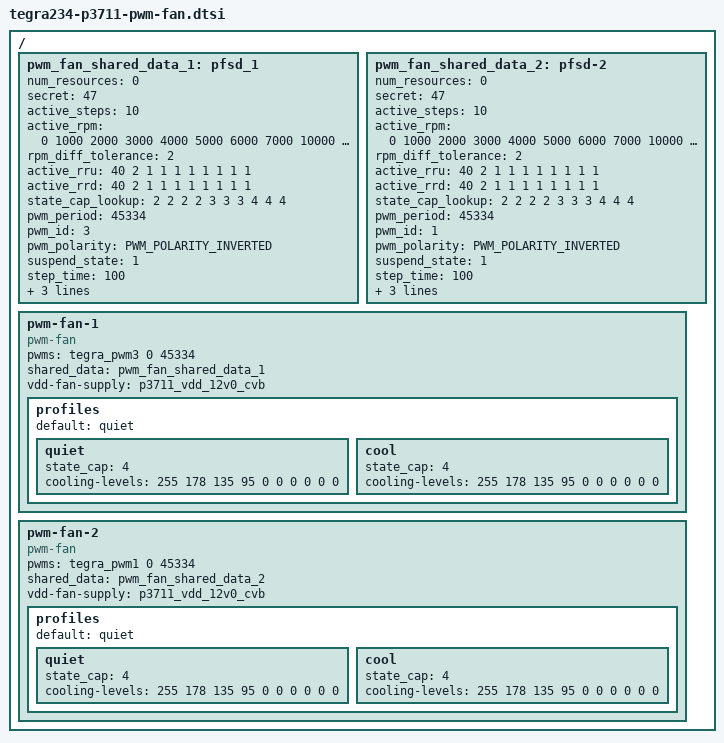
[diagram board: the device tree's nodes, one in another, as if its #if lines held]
/*
 * Copyright (c) 2021, NVIDIA CORPORATION.  All rights reserved.
 *
 * This program is free software; you can redistribute it and/or modify it
 * under the terms and conditions of the GNU General Public License,
 * version 2, as published by the Free Software Foundation.
 *
 * This program is distributed in the hope it will be useful, but WITHOUT
 * ANY WARRANTY; without even the implied warranty of MERCHANTABILITY or
 * FITNESS FOR A PARTICULAR PURPOSE.  See the GNU General Public License for
 * more details.
 *
 * You should have received a copy of the GNU General Public License
 * along with this program.  If not, see <http://www.gnu.org/licenses/>.
 */
#include <dt-bindings/gpio/tegra234-gpio.h>
#include <dt-bindings/pwm/pwm.h>

/ {
	pwm_fan_shared_data_1: pfsd_1 {
		num_resources = <0>;
		secret = <47>;
		active_steps = <10>;
		active_rpm = <0 1000 2000 3000 4000 5000 6000 7000 10000 11000>;
		rpm_diff_tolerance = <2>;
		active_rru = <40 2 1 1 1 1 1 1 1 1>;
		active_rrd = <40 2 1 1 1 1 1 1 1 1>;
		state_cap_lookup = <2 2 2 2 3 3 3 4 4 4>;
		pwm_period = <45334>;
		/* TODO: Check correctness of PWM controller ID when pinmux sheet is available */
		pwm_id = <3>;
		pwm_polarity = <PWM_POLARITY_INVERTED>;
		suspend_state = <1>;
		step_time = <100>; /* mesecs */
		state_cap = <7>;
		active_pwm_max = <256>;
		tach_period = <1000>;
		/* TODO: Fix when pinmux sheet is available */
		//pwm_gpio = <&tegra_aon_gpio TEGRA234_AON_GPIO(CC, 4) GPIO_ACTIVE_LOW>;
	};

	pwm_fan_shared_data_2: pfsd-2 {
		num_resources = <0>;
		secret = <47>;
		active_steps = <10>;
		active_rpm = <0 1000 2000 3000 4000 5000 6000 7000 10000 11000>;
		rpm_diff_tolerance = <2>;
		active_rru = <40 2 1 1 1 1 1 1 1 1>;
		active_rrd = <40 2 1 1 1 1 1 1 1 1>;
		state_cap_lookup = <2 2 2 2 3 3 3 4 4 4>;
		pwm_period = <45334>;
		/* TODO: Check correctness of PWM controller ID when pinmux sheet is available */
		pwm_id = <1>;
		pwm_polarity = <PWM_POLARITY_INVERTED>;
		suspend_state = <1>;
		step_time = <100>; /* mesecs */
		state_cap = <7>;
		active_pwm_max = <256>;
		tach_period = <1000>;
		/* TODO: Fix when pinmux sheet is available */
		//pwm_gpio = <&tegra_aon_gpio TEGRA234_AON_GPIO(CC, 4) GPIO_ACTIVE_LOW>;
	};

	/* PWM FAN on J16 */
	pwm-fan-1 {
		compatible = "pwm-fan";
		status = "okay";
		#pwm-cells = <1>;
		/* TODO: Check correctness of PWM controller ID when pinmux sheet is available */
		pwms = <&tegra_pwm3 0 45334>;
		shared_data = <&pwm_fan_shared_data_1>;
		vdd-fan-supply = <&p3711_vdd_12v0_cvb>;
		profiles {
			default = "quiet";
			quiet {
				state_cap = <4>;
#if TEGRA_PWM_FAN_DT_VERSION == DT_VERSION_2
				cooling-levels = <255 178 135 95 0 0 0 0 0 0>;
#else
				active_pwm = <0 77 120 160 255 255 255 255 255 255>;
#endif
			};
			cool {
				state_cap = <4>;
#if TEGRA_PWM_FAN_DT_VERSION == DT_VERSION_2
				cooling-levels = <255 178 135 95 0 0 0 0 0 0>;
#else
				active_pwm = <0 77 120 160 255 255 255 255 255 255>;
#endif
			};
		};
	};

	/* PWM FAN on J17 */
	pwm-fan-2 {
		compatible = "pwm-fan";
		status = "okay";
		#pwm-cells = <1>;
		/* TODO: Check correctness of PWM controller ID when pinmux sheet is available */
		pwms = <&tegra_pwm1 0 45334>;
		shared_data = <&pwm_fan_shared_data_2>;
		vdd-fan-supply = <&p3711_vdd_12v0_cvb>;
		profiles {
			default = "quiet";
			quiet {
				state_cap = <4>;
#if TEGRA_PWM_FAN_DT_VERSION == DT_VERSION_2
				cooling-levels = <255 178 135 95 0 0 0 0 0 0>;
#else
				active_pwm = <0 77 120 160 255 255 255 255 255 255>;
#endif
			};
			cool {
				state_cap = <4>;
#if TEGRA_PWM_FAN_DT_VERSION == DT_VERSION_2
				cooling-levels = <255 178 135 95 0 0 0 0 0 0>;
#else
				active_pwm = <0 77 120 160 255 255 255 255 255 255>;
#endif
			};
		};
	};
};

